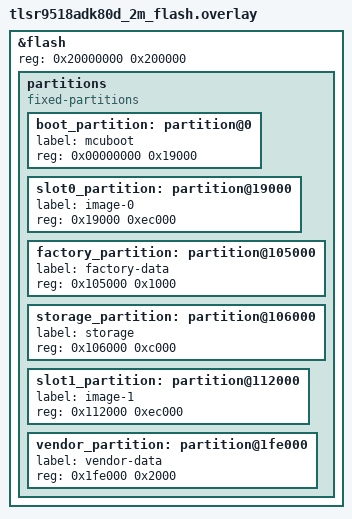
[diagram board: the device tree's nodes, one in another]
&flash {
	reg = <0x20000000 0x200000>;

	/delete-node/ partitions;
	partitions {
		compatible = "fixed-partitions";
		#address-cells = <1>;
		#size-cells = <1>;

		boot_partition: partition@0 {
			label = "mcuboot";
			reg = <0x00000000 0x19000>;
		};
		slot0_partition: partition@19000 {
			label = "image-0";
			reg = <0x19000 0xec000>;
		};
		factory_partition: partition@105000 {
			label = "factory-data";
			reg = <0x105000 0x1000>;
		};
		storage_partition: partition@106000 {
			label = "storage";
			reg = <0x106000 0xc000>;
		};
		slot1_partition: partition@112000 {
			label = "image-1";
			reg = <0x112000 0xec000>;
		};
		vendor_partition: partition@1fe000 {
			label = "vendor-data";
			reg = <0x1fe000 0x2000>;
		};
	};
};
